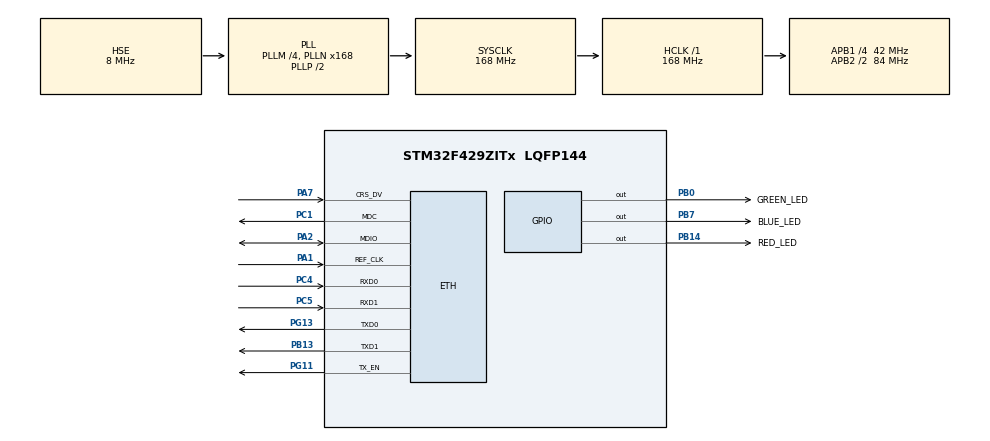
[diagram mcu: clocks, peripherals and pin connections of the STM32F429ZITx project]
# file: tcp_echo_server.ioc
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Mcu.Family=STM32F4
RCC.PLLSourceVirtual=RCC_PLLSOURCE_HSE
RCC.CortexFreq_Value=168000000
PA7.Mode=RMII
PB14.GPIO_Label=RED_LED
PC4.Signal=ETH_RXD0
PC14/OSC32_IN.Mode=LSE-External-Oscillator
PB0.GPIO_Label=GREEN_LED
LWIP.LWIP_DHCP=0
PC5.Mode=RMII
RCC.APB1CLKDivider=RCC_HCLK_DIV4
PB13.Signal=ETH_TXD1
PG13.Signal=ETH_TXD0
ETH.PhyAddress=0
PG11.Signal=ETH_TX_EN
RCC.SYSCLKSource=RCC_SYSCLKSOURCE_PLLCLK
ProjectManager.StackSize=0x4000
VP_LWIP_VS_Enabled.Mode=Enabled
LWIP.GATEWAY_ADDRESS=192.168.192.001
LWIP.NETMASK_ADDRESS=255.255.255.000
PA13.Signal=SYS_JTMS-SWDIO
ProjectManager.TargetToolchain=STM32CubeIDE
PH0/OSC_IN.Mode=HSE-External-Clock-Source
RCC.HCLKFreq_Value=168000000
RCC.APB2TimFreq_Value=168000000
PH1/OSC_OUT.Signal=RCC_OSC_OUT
PA1.Signal=ETH_REF_CLK
RCC.AHBFreq_Value=168000000
PB14.Signal=GPIO_Output
RCC.HSE_VALUE=8000000
board=custom
RCC.VCOOutputFreq_Value=336000000
PH0/OSC_IN.Signal=RCC_OSC_IN
RCC.APB2Freq_Value=84000000
PA1.Mode=RMII
PA14.Mode=Serial_Wire
PB7.Signal=GPIO_Output
PG13.Mode=RMII
PA13.Mode=Serial_Wire
PH1/OSC_OUT.Mode=HSE-External-Clock-Source
Mcu.Name=STM32F429ZITx
PA2.Signal=ETH_MDIO
PB7.GPIO_Label=BLUE_LED
RCC.48MHZClocksFreq_Value=84000000
RCC.SYSCLKFreq_VALUE=168000000
Mcu.Package=LQFP144
ETH.MediaInterface=ETH_MEDIA_INTERFACE_RMII
PC14/OSC32_IN.Signal=RCC_OSC32_IN
PC15/OSC32_OUT.Mode=LSE-External-Oscillator
PG11.Mode=RMII
PA14.Signal=SYS_JTCK-SWCLK
ProjectManager.HeapSize=0x2000
LWIP.Version=v2.1.2_Cube
RCC.HSI_VALUE=16000000
NVIC.PriorityGroup=NVIC_PRIORITYGROUP_4
RCC.APB2CLKDivider=RCC_HCLK_DIV2
RCC.PLLM=4
RCC.PLLN=168
RCC.APB1TimFreq_Value=84000000
PA2.Mode=RMII
PC15/OSC32_OUT.Signal=RCC_OSC32_OUT
PC5.Signal=ETH_RXD1
PB13.Mode=RMII
RCC.APB1Freq_Value=42000000
PB0.Signal=GPIO_Output
PC1.Signal=ETH_MDC
PC4.Mode=RMII
LWIP.IP_ADDRESS=192.168.001.003
PC1.Mode=RMII
PA7.Signal=ETH_CRS_DV

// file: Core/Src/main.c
/* USER CODE BEGIN Header */
/**
  ******************************************************************************
  * @file           : main.c
  * @brief          : Main program body
  ******************************************************************************
  * @attention
  *
  * <h2><center>&copy; Copyright (c) 2022 STMicroelectronics.
  * All rights reserved.</center></h2>
  *
  * This software component is licensed by ST under BSD 3-Clause license,
  * the "License"; You may not use this file except in compliance with the
  * License. You may obtain a copy of the License at:
  *                        opensource.org/licenses/BSD-3-Clause
  *
  ******************************************************************************
  */
/* USER CODE END Header */
#include "main.h"
#include "lwip.h"
#include "gpio.h"

/* USER CODE BEGIN Includes */
#include "tcp_echo.h"
/* USER CODE END Includes */

/* USER CODE BEGIN PV */
extern struct netif gnetif;
/* USER CODE END PV */

void SystemClock_Config(void);

/* USER CODE BEGIN 0 */
void ethernetif_notify_conn_changed(struct netif* netif)
{
	if (netif_is_link_up(netif))
	{
		HAL_GPIO_WritePin(GREEN_LED_GPIO_Port, GREEN_LED_Pin, GPIO_PIN_SET);
		HAL_GPIO_WritePin(RED_LED_GPIO_Port, RED_LED_Pin, GPIO_PIN_RESET);
	}
	else
	{
		HAL_GPIO_WritePin(GREEN_LED_GPIO_Port, GREEN_LED_Pin, GPIO_PIN_RESET);
		HAL_GPIO_WritePin(RED_LED_GPIO_Port, RED_LED_Pin, GPIO_PIN_SET);
	}
}

/* USER CODE END 0 */

int main(void)
{

  /* MCU Configuration--------------------------------------------------------*/

  /* Reset of all peripherals, Initializes the Flash interface and the Systick. */
  HAL_Init();

  /* Configure the system clock */
  SystemClock_Config();

  /* Initialize all configured peripherals */
  MX_GPIO_Init();
  MX_LWIP_Init();
  /* USER CODE BEGIN 2 */
  ethernetif_notify_conn_changed(&gnetif);
  tcp_echoserver_init();

  /* USER CODE END 2 */

  /* Infinite loop */
  while (1)
  {

    /* USER CODE BEGIN 3 */
	  MX_LWIP_Process();
  }
  /* USER CODE END 3 */
}

void SystemClock_Config(void)
{
  RCC_OscInitTypeDef RCC_OscInitStruct = {0};
  RCC_ClkInitTypeDef RCC_ClkInitStruct = {0};

  /** Configure the main internal regulator output voltage
  */
  __HAL_RCC_PWR_CLK_ENABLE();
  __HAL_PWR_VOLTAGESCALING_CONFIG(PWR_REGULATOR_VOLTAGE_SCALE1);
  /** Initializes the RCC Oscillators according to the specified parameters
  * in the RCC_OscInitTypeDef structure.
  */
  RCC_OscInitStruct.OscillatorType = RCC_OSCILLATORTYPE_HSE;
  RCC_OscInitStruct.HSEState = RCC_HSE_BYPASS;
  RCC_OscInitStruct.PLL.PLLState = RCC_PLL_ON;
  RCC_OscInitStruct.PLL.PLLSource = RCC_PLLSOURCE_HSE;
  RCC_OscInitStruct.PLL.PLLM = 4;
  RCC_OscInitStruct.PLL.PLLN = 168;
  RCC_OscInitStruct.PLL.PLLP = RCC_PLLP_DIV2;
  RCC_OscInitStruct.PLL.PLLQ = 4;
  if (HAL_RCC_OscConfig(&RCC_OscInitStruct) != HAL_OK)
  {
    Error_Handler();
  }
  /** Initializes the CPU, AHB and APB buses clocks
  */
  RCC_ClkInitStruct.ClockType = RCC_CLOCKTYPE_HCLK|RCC_CLOCKTYPE_SYSCLK
                              |RCC_CLOCKTYPE_PCLK1|RCC_CLOCKTYPE_PCLK2;
  RCC_ClkInitStruct.SYSCLKSource = RCC_SYSCLKSOURCE_PLLCLK;
  RCC_ClkInitStruct.AHBCLKDivider = RCC_SYSCLK_DIV1;
  RCC_ClkInitStruct.APB1CLKDivider = RCC_HCLK_DIV4;
  RCC_ClkInitStruct.APB2CLKDivider = RCC_HCLK_DIV2;

  if (HAL_RCC_ClockConfig(&RCC_ClkInitStruct, FLASH_LATENCY_5) != HAL_OK)
  {
    Error_Handler();
  }
}

void Error_Handler(void)
{
  __disable_irq();
  while (1)
  {
  }
}

/************************ (C) COPYRIGHT STMicroelectronics *****END OF FILE****/
